# TC37X register map
File version: 1.0.0
CPU: CM4 r0p1, little endian, MPU, FPU, VTOR, 3 interrupt priority bits
Registers are 16-bit, read-write, reset 0x0 unless marked. A register's access mark holds for its fields unless they carry their own. Offsets are from the block's base; [hi:lo] are bit positions; {n}, {i} and the like mark numbered series; 'fields as' and 'values as' point back to an identical list.

## CBS — ce_cbs
Base 0xF0000400
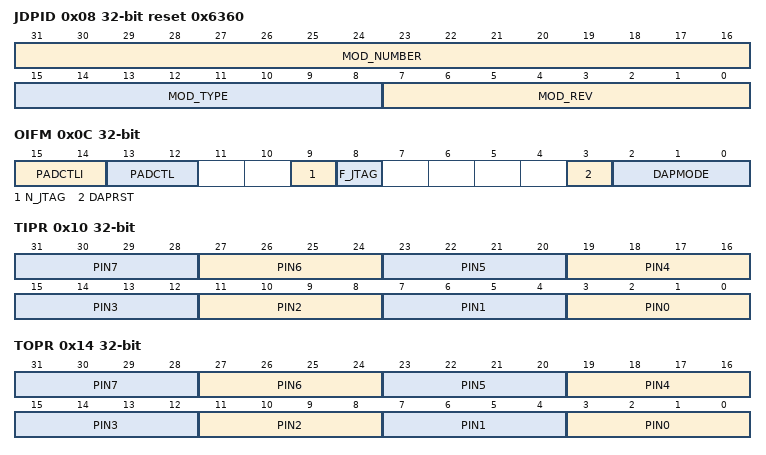
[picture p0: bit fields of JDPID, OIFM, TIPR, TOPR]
0x08 JDPID 32-bit ro reset 0x6360 — Module Identification Register
  [31:16] MOD_NUMBER — Module Number - MOD_NUMBER
  [15:8] MOD_TYPE — Module Type - MOD_TYPE
  [7:0] MOD_REV — Module Revision - MOD_REV
0x0C OIFM 32-bit — OCDS Interface Mode Register
  [15:14] PADCTLI — Pad input threshold control for Debug Interface Pins
  [13:12] PADCTL — Pad Control for Debug Interface Pins
  [9] N_JTAG — No Switch to JTAG
  [8] F_JTAG — Forced JTAG Mode
  [3] DAPRST — DAPProtocol Clear - DAPRST
  [2:0] DAPMODE — DAPInterface Mode - DAPMODE
0x10 TIPR 32-bit — TG Input Pins Routing
  [4n+3:4n] PIN{n} (n=0..7) — Trigger Pin {n} to Trigger Line Routing
0x14 TOPR 32-bit — TG Output Pins Routing
  [4n+3:4n] PIN{n} (n=0..7) — Trigger Line to Trigger Pin {n} Routing
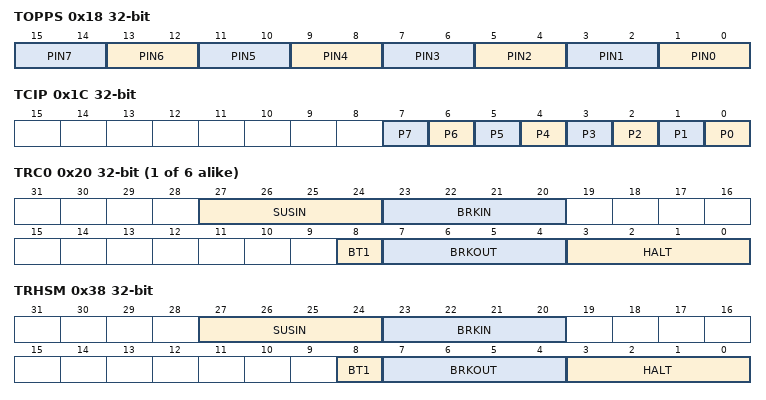
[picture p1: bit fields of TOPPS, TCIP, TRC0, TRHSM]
0x18 TOPPS 32-bit — TG Output Pins Pulse Stretcher
  [2n+1:2n] PIN{n} (n=0..7) — Pulse Stretch Control for Trigger Pin {n} - PIN{n}
0x1C TCIP 32-bit ro — TG Capture for TG Input Pins
  [n] P{n} (n=0..7) — Capture of Trigger Input Pin {n} - P{n}
{0x20+4i} TRC{i} 32-bit (i=0..5) — TG Routing for CPU{i}
  [27:24] SUSIN — Trigger Line to SUSIN Routing - SUSIN
  [23:20] BRKIN — Trigger Line to BRKIN Routing - BRKIN
  [8] BT1 — BRKOUT to Trigger Line 1 Routing - BT1
  [7:4] BRKOUT — BRKOUT to Trigger Line Routing - BRKOUT
  [3:0] HALT — HALT to Trigger Line Routing - HALT
0x38 TRHSM 32-bit — TG Routing for HSMControl
  fields as TRC0
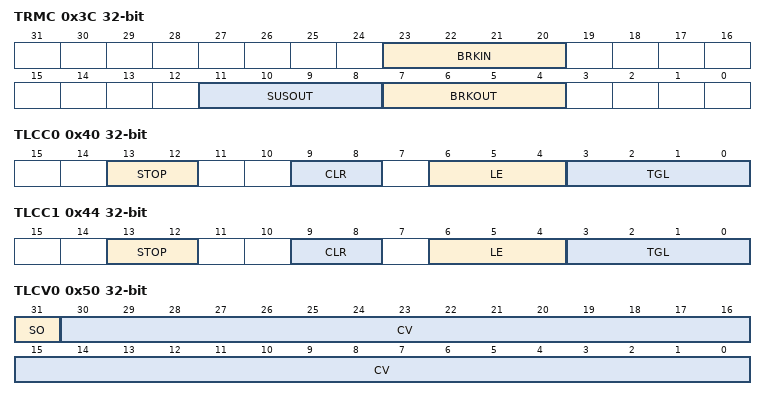
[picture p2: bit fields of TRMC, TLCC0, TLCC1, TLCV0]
0x3C TRMC 32-bit — TG Routing for MCDS Control
  [23:20] BRKIN — Trigger Line to MCDS break_in Routing - BRKIN
  [11:8] SUSOUT — MCDS suspend_out to Trigger Line Routing - SUSOUT
  [7:4] BRKOUT — MCDS break_out to Trigger Line Routing - BRKOUT
0x40 TLCC0 32-bit — TG Line Counter Control
  [13:12] STOP wo — Stop Counter(s) - STOP
  [9:8] CLR wo — Clear and Enable Counter(s) - CLR
  [6:4] LE — Level or Edge Counting - LE
  [3:0] TGL — Trigger Line to Counter Routing - TGL
0x44 TLCC1 32-bit — TG Line Counter Control
  fields as TLCC0
0x50 TLCV0 32-bit ro — TG Line Counter Value
  [31] SO — Sticky Overflow Bit - SO
  [30:0] CV — Count Value - CV
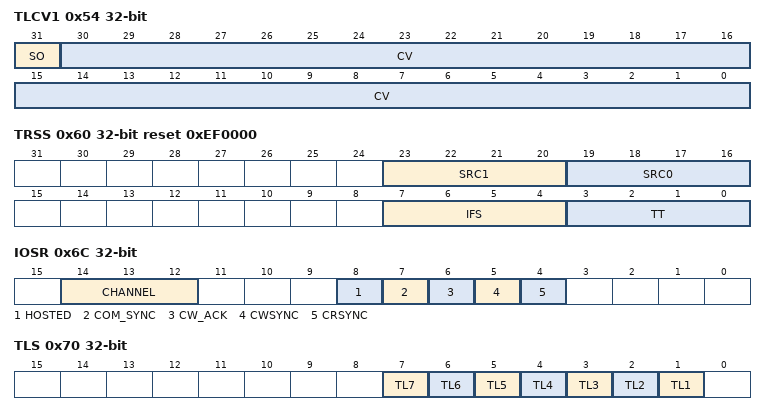
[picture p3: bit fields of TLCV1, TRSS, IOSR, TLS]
0x54 TLCV1 32-bit ro — TG Line Counter Value
  [31] SO — Sticky Overflow Bit - SO
  [30:0] CV — Count Value - CV
0x60 TRSS 32-bit reset 0xEF0000 — TG Routing for Special Signals
  [23:20] SRC1 — Trigger Line to SRC1 Interrupt Routing - SRC1
  [19:16] SRC0 — Trigger Line to SRC0 Interrupt Routing - SRC0
  [7:4] IFS — Trigger Line to Fault and Stress Injection Routing - IFS
  [3:0] TT — Trigger Line to Cerberus Triggered Transfer Routing - TT
0x64 JTAGID 32-bit reset not defined — JTAGDevice Identification Register
  [31:0] JTAG_ID — JTAGDevice ID - JTAG_ID
0x68 COMDATA 32-bit — Communication Mode Data Register
  [31:0] DATA — Read/Write Data - DATA
0x6C IOSR 32-bit — IOClientStatus and Control Register
  [14:12] CHANNEL ro — Channel Indication - CHANNEL
  [8] HOSTED ro — Tool Interface in Use - HOSTED
  [7] COM_SYNC ro — Communication Mode Synchronization Flag - COM_SYNC
  [6] CW_ACK wo — Communication Mode Write Acknowledge - CW_ACK
  [5] CWSYNC ro — Communication Mode Write Sync Flag - CWSYNC
  [4] CRSYNC ro — Communication Mode Read Sync Flag - CRSYNC
0x70 TLS 32-bit ro — TG Line State
  [n] TL{n} (n=1..7) — Current State of Trigger Line {n} - TL{n}
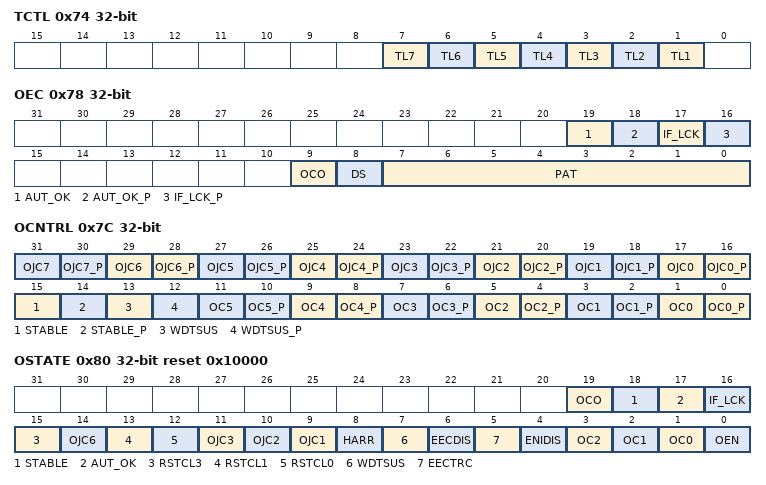
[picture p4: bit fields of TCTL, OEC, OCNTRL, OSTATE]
0x74 TCTL 32-bit ro — TG Capture for TG Lines
  [n] TL{n} (n=1..7) — Capture of Trigger Line {n} - TL{n}
0x78 OEC 32-bit wo — OCDS Enable Control Register
  [19] AUT_OK — Set/Clear the Authorization OK Indication - AUT_OK
  [18] AUT_OK_P — AUT_OK Write Protection - AUT_OK_P
  [17] IF_LCK — Set/Clear Interface Locked Indication - IF_LCK
  [16] IF_LCK_P — IF_LCK Write Protection - IF_LCK_P
  [9] OCO — OCDS Clock Off - OCO
  [8] DS — Disable OCDS - DS
  [7:0] PAT — OCDS Enabling Pattern - PAT
0x7C OCNTRL 32-bit wo — OSCU Control Register
  [2n+17] OJC{n} (n=0..7) — Set/Clear OCDS Control Bits IOClient Domain - OJC{n}
  [2n+16] OJC{n}_P (n=0..7) — OJC{n} Write Protection - OJC{n}_P
  [15] STABLE — InitializeApplication ResetIndication - STABLE
  [14] STABLE_P — STABLE Write Protection - STABLE_P
  [13] WDTSUS — Set/Clear Watchdog Timer Suspension Control - WDTSUS
  [12] WDTSUS_P — WDTSUS Write Protection - WDTSUS_P
  [2n+1] OC{n} (n=0..5) — Set/Clear OCDS Control Bits Bus Domain - OC{n}
  [2n] OC{n}_P (n=0..5) — OC{n} Write Protection - OC{n}_P
0x80 OSTATE 32-bit ro reset 0x10000 — OSCUStatus Register
  [19] OCO — OCDS debug resource Clock On Indication - OCO
  [18] STABLE — Application Reset Indication - STABLE
  [17] AUT_OK — Authorization OK Indication - AUT_OK
  [16] IF_LCK — Interface Locked Indication - IF_LCK
  [15] RSTCL3 — OCDS Application Reset Request - RSTCL3
  [14] OJC6 — OCDS Control Bits IOClient Domain OJC6
  [13] RSTCL1 — OCDS Debug Reset Request - RSTCL1
  [12] RSTCL0 — OCDS System Reset Request - RSTCL0
  [11] OJC3 — OCDS Control Bits IOClient Domain OJC3
  [10] OJC2 — OCDS Control Bits IOClient Domain OJC2
  [9] OJC1 — OCDS Control Bits IOClient Domain OJC1
  [8] HARR — Halt after Reset Request - HARR
  [7] WDTSUS — Control of Watchdog Timer (WDT) Suspension - WDTSUS
  [6] EECDIS — Emulation Logic Disable - EECDIS
  [5] EECTRC — On Chip Trace Enable - EECTRC
  [4] ENIDIS — OCDS ENDINIT Protection Override - ENIDIS
  [3] OC2 — OCDS Control Bits System Bus Domain - OC2
  [2] OC1 — OCDS Control Bits System Bus Domain - OC1
  [1] OC0 — OCDS Control Bits System Bus Domain - OC0
  [0] OEN — OCDS Enabled Flag - OEN
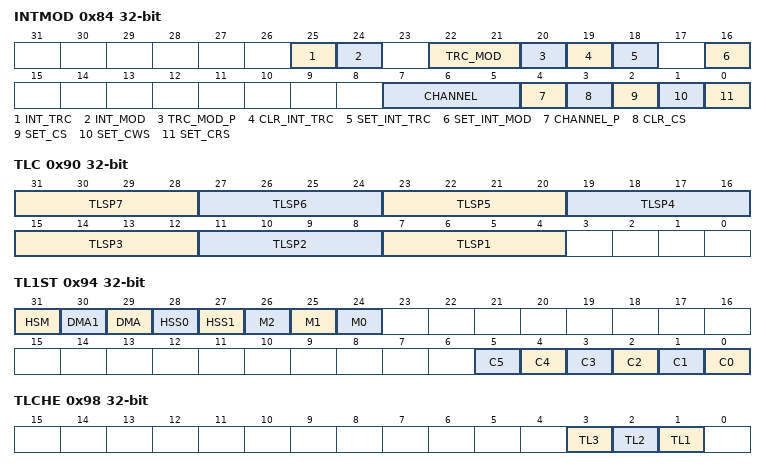
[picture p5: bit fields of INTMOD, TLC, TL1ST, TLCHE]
0x84 INTMOD 32-bit — Internal Mode Status and Control Register
  [25] INT_TRC ro — Internally Controlled Triggered Transfer Enable - INT_TRC
  [24] INT_MOD ro — Internal Mode Enabled Flag - INT_MOD
  [22:21] TRC_MOD — Data Size Definition for Triggered Transfer - TRC_MOD
  [20] TRC_MOD_P wo — TRC_MOD Write Protection - TRC_MOD_P
  [19] CLR_INT_TRC wo — Disable Internally Controlled Triggered Transfer - CLR_INT_TRC
  [18] SET_INT_TRC wo — Enable Internally Controlled Triggered Transfer - SET_INT_TRC
  [16] SET_INT_MOD wo — Enter Internal Mode - SET_INT_MOD
  [7:5] CHANNEL — Channel Indication - CHANNEL
  [4] CHANNEL_P wo — CHANNEL Write Protection - CHANNEL_P
  [3] CLR_CS wo — Clear Communication Synchronization Flag - CLR_CS
  [2] SET_CS wo — Set Communication Synchronization Flag - SET_CS
  [1] SET_CWS wo — Set Write Sync Flag - SET_CWS
  [0] SET_CRS wo — Set Read Sync Flag - SET_CRS
0x88 ICTSA 32-bit — Internally Controlled Trace Source Register
  [31:0] ADDR — Source Address - ADDR
0x8C ICTTA 32-bit reset 0x10F068 — Internally Controlled Trace Destination Register
  [31:0] ADDR — Destination Address - ADDR
0x90 TLC 32-bit — TG Line Control
  [4n+3:4n] TLSP{n} (n=1..7) — TG Line Signal Processing - TLSP{n}
0x94 TL1ST 32-bit — TG Line 1 Suspend Targets
  [31] HSM — HSM as Suspend Target - HSM
  [30] DMA1 — DMA as Suspend Target - DMA1
  [29] DMA — DMA as Suspend Target - DMA
  [28] HSS0 — HSSL0 as Suspend Target - HSS0
  [27] HSS1 — HSSL1 as Suspend Target - HSS1
  [26] M2 — Master 2 as Suspend Target
  [25] M1 — Master 1 as Suspend Target
  [24] M0 — Master 0 as Suspend Target
  [n] C{n} (n=0..5) — CPU{n} as Suspend Target - C{n}
0x98 TLCHE 32-bit — TG Line Capture and Hold Enable
  [3] TL3 — Capture and Hold Enable for Trigger Line 3 - TL3
  [2] TL2 — Capture and Hold Enable for Trigger Line 2 - TL2
  [1] TL1 — Capture and Hold Enable for Trigger Line 1 - TL1
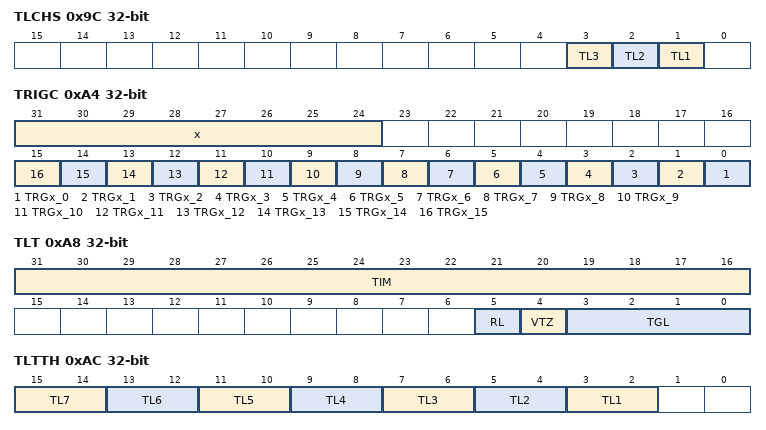
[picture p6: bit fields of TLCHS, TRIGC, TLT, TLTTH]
0x9C TLCHS 32-bit wo — TG Line Capture and Hold Clear
  [3] TL3 — Capture and Hold Clear for Trigger Line 3 - TL3
  [2] TL2 — Capture and Hold Clear for Trigger Line 2 - TL2
  [1] TL1 — Capture and Hold Clear for Trigger Line 1 - TL1
0xA0 TRIGS 32-bit wo — Set Trigger to Host Register
  [7:0] BITNUM — Service Request Bit Number to Set - BITNUM
0xA4 TRIGC 32-bit ro — Clear Trigger to Host Register
  [31:24] x — Index of most important register TRIGx - x
  [n] TRGx_{n} (n=0..15) — Request Bits of most important register TRIGx - TRGx_{n}
0xA8 TLT 32-bit — TG Line Timer
  [31:16] TIM — Timer Value - TIM
  [5] RL — Reload Timer - RL
  [4] VTZ — TG Line Value when Timer Value is Zero - VTZ
  [3:0] TGL — Timer to Trigger Line Routing - TGL
0xAC TLTTH 32-bit — TG Lines for Trigger to Host
  [2n+1:2n] TL{n} (n=1..7) — TG Line Enabling for Trigger to Host (TRIG) - TL{n}
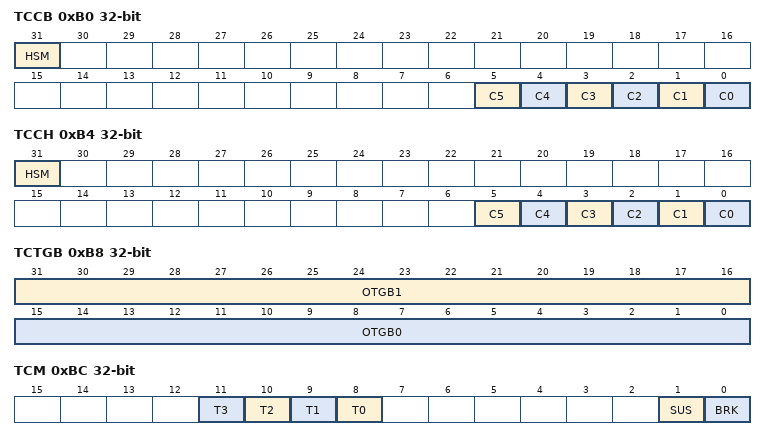
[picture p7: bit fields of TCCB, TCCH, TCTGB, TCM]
0xB0 TCCB 32-bit ro — TG Capture for Cores - BRKOUT
  [31] HSM — Capture of BRKOUT Signal ofHSM - HSM
  [n] C{n} (n=0..5) — Capture of BRKOUT Signal of CPU{n} - C{n}
0xB4 TCCH 32-bit ro — TG Capture for Cores - HALT
  [31] HSM — Capture of HALT Signal ofHSM - HSM
  [n] C{n} (n=0..5) — Capture of HALT Signal of CPU{n} - C{n}
0xB8 TCTGB 32-bit ro — TG Capture for OTGB0/1
  [31:16] OTGB1 — Capture Bits for OTGB1 - OTGB1
  [15:0] OTGB0 — Capture Bits for OTGB0 - OTGB0
0xBC TCM 32-bit ro — TG Capture for MCDS
  [n+8] T{n} (n=0..3) — Capture of MCDS trig_out {n} - T{n}
  [1] SUS — Capture of MCDS suspend_out - SUS
  [0] BRK — Capture of MCDS break_out - BRK
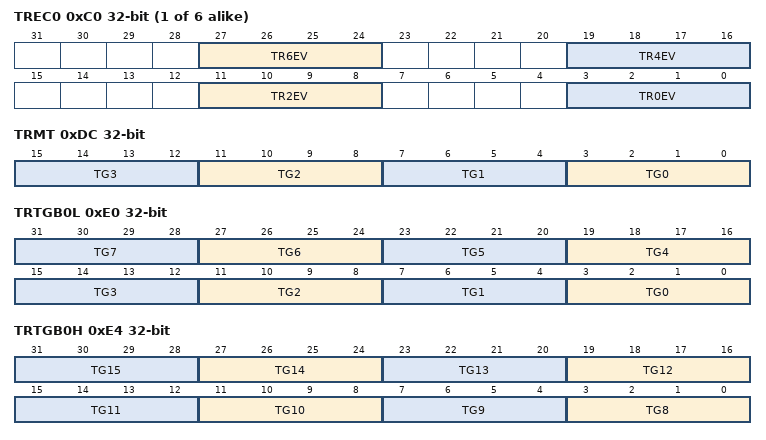
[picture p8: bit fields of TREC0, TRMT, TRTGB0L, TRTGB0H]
{0xC0+4i} TREC{i} 32-bit (i=0..5) — TG Routing Events of CPU{i}
  [27:24] TR6EV — TRxEVT to Trigger Line Routing TR6EV
  [19:16] TR4EV — TRxEVT to Trigger Line Routing TR4EV
  [11:8] TR2EV — TRxEVT to Trigger Line Routing TR2EV
  [3:0] TR0EV — TRxEVT to Trigger Line Routing TR0EV
0xDC TRMT 32-bit — TG Routing for MCDS Triggers
  [4n+3:4n] TG{n} (n=0..3) — MCDS trig_out {n} to Trigger Line Routing - TG{n}
0xE0 TRTGB0L 32-bit — TG Routing for OTGBi Bits [7:0]
  [4n+3:4n] TG{n} (n=0..7) — OTGBi Bit {n} to Trigger Line Routing - TG{n}
0xE4 TRTGB0H 32-bit — TG Routing for OTGBi Bits [15:8]
  [4n-29:4n-32] TG{n} (n=8..15) — OTGBi Bit {n} to Trigger Line Routing - TG{n}
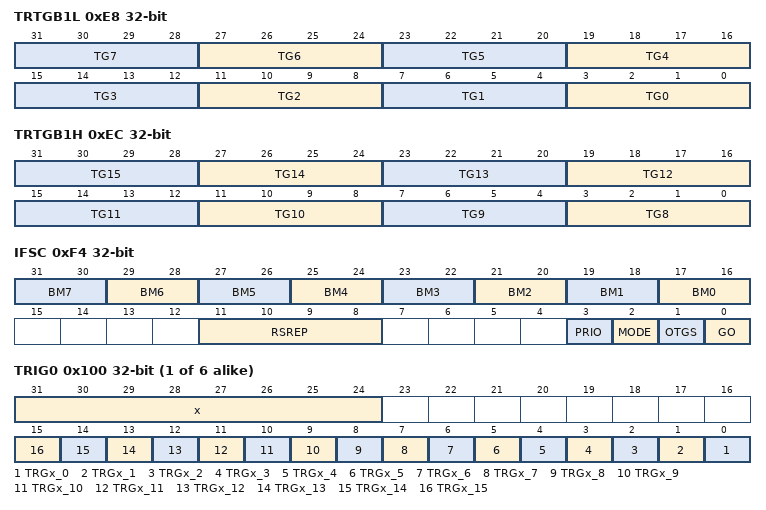
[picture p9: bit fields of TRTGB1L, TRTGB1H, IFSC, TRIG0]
0xE8 TRTGB1L 32-bit — TG Routing for OTGBi Bits [7:0]
  fields as TRTGB0L
0xEC TRTGB1H 32-bit — TG Routing for OTGBi Bits [15:8]
  fields as TRTGB0H
0xF0 IFSA 32-bit — IFS Address Register
  [31:0] ADDR — Address for FI/SI Accesses - ADDR
0xF4 IFSC 32-bit — IFS Control Register
  [2n+17:2n+16] BM{n} (n=0..7) — Fault Injection Bit Manipulation - BM{n}
  [11:8] RSREP — Read Stress Repetitions
  [3] PRIO — Bus Master Priority - PRIO
  [2] MODE — Stress or Fault Injection Mode - MODE
  [1] OTGS — Injection Trigger by OTGS - OTGS
  [0] GO wo — Injection Trigger - GO
{0x100+4i} TRIG{i} 32-bit ro (reset mask 0xFFFFFF) (i=0..5) — Trigger to Host Register {i}
  [31:24] x — TRIG register number - x
  [n] TRGx_{n} (n=0..15) — Service Request Bits - TRGx_{n}
0x1F8 ACCEN1 32-bit ro — Access Enable Register 1
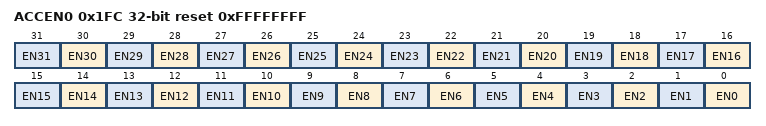
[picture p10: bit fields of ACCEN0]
0x1FC ACCEN0 32-bit reset 0xFFFFFFFF — Access Enable Register 0
  [n] EN{n} (n=0..31) — Access Enable for Master TAG ID {n} - EN{n}
